# SSE320 register map
Vendor: ARM Ltd.; Series: ARMv8.1-M Mainline; File version: 1.0
CPU: CM85 r0p0, little endian, MPU, FPU, 3 interrupt priority bits, 8 SAU regions
Registers are 32-bit, read-write, reset 0x0 unless marked. A register's access mark holds for its fields unless they carry their own. Offsets are from the block's base; [hi:lo] are bit positions; {n}, {i} and the like mark numbered series.

## UART0
Base 0x48203000
Same registers: UART1 0x48204000, UART2 0x48205000, UART3 0x48206000, UART4 0x48207000, UART5 0x48208000, UART0_Secure 0x58203000, UART1_Secure 0x58204000, UART2_Secure 0x58205000, UART3_Secure 0x58206000, UART4_Secure 0x58207000, UART5_Secure 0x58208000
0x00 DATA 8-bit — Receive and Transmit Data Value
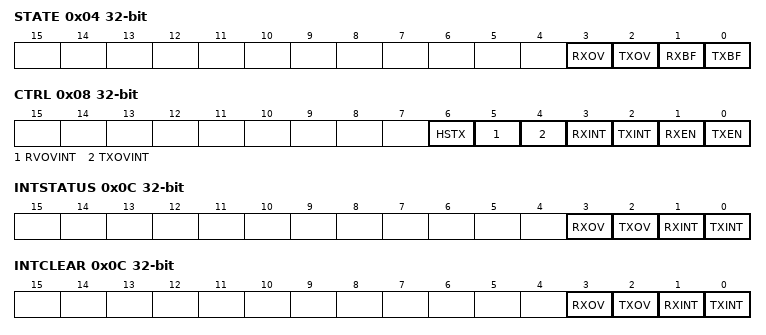
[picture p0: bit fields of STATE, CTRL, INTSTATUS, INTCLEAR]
0x04 STATE — UART Status Register
  [3] RXOV write-1-clears — RX Buffer Overun (write 1 to clear)
  [2] TXOV write-1-clears — TX Buffer Overun (write 1 to clear)
  [1] RXBF ro — RX Buffer Full
  [0] TXBF ro — TX Buffer Full
0x08 CTRL — UART Control Register
  [all] fields
    0=Disabled; 1=Enabled
  [6] HSTX — High Speed Test Mode for TX only
  [5] RVOVINT — RX Overrun Interrupt Enable
  [4] TXOVINT — TX Overrun Interrupt Enable
  [3] RXINT — RX Interrupt Enable
  [2] TXINT — TX Interrupt Enable
  [1] RXEN — RX Enable
  [0] TXEN — TX Enable
0x0C INTSTATUS ro — UART Interrupt Status Register
  [3] RXOV — RX Overrun Interrupt
  [2] TXOV — TX Overrun Interrupt
  [1] RXINT — RX Interrupt
  [0] TXINT — TX Interrupt
0x0C INTCLEAR wo (alternate view of INTSTATUS) — UART Interrupt CLEAR Register
  [3] RXOV write-1-clears — RX Overrun Interrupt
  [2] TXOV write-1-clears — TX Overrun Interrupt
  [1] RXINT write-1-clears — RX Interrupt
  [0] TXINT write-1-clears — TX Interrupt
0x10 BAUDDIV — Baudrate Divider

## I2C0 — I2C Touch
Base 0x48100000
Same registers: I2C1 0x48105000, I2C2 0x48106000, I2C3 0x48108000, I2C3 0x48109000, I2C0_Secure 0x58100000, I2C2 0x58105000, I2C3 0x58106000, I2C3 0x58108000, I2C3 0x58109000
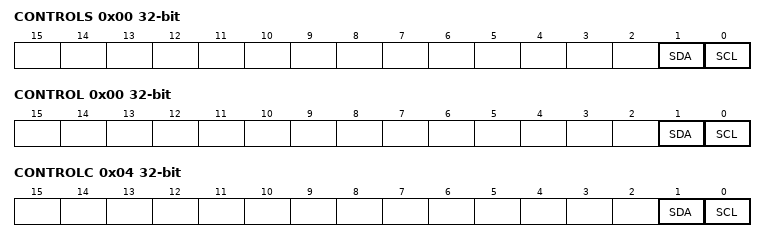
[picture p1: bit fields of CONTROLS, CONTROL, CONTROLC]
0x00 CONTROLS wo — Control Set
  [1] SDA — Serial data line
  [0] SCL — Serial clock line
0x00 CONTROL ro (alternate view of CONTROLS) — Control Status
  [1] SDA — Serial data line
  [0] SCL — Serial clock line
0x04 CONTROLC — Control Clear
  [1] SDA — Serial data line
  [0] SCL — Serial clock line

## WATCHDOG — Non-secure Watchdog Timer
Base 0x48040000
Same registers: WATCHDOG_Secure 0x58040000
0x00 WCS — Watchdog control and Status.
0x08 WOR — Watchdog Offset Register.
0x10 WCV_LOW — Watchdog Compare Value Lower Word.
0x14 WCV_HIGH — Watchdog Compare Value Higher Word.
0xFCC CNT_W_IIDR ro reset 0x143B — Control Frame Watchdog Interface Identification Register.
0x1000 WRR wo — Watchdog Refresh Register.
0x1FCC REF_W_IIDR ro reset 0x143B — Refresh Frame Watchdog Interface Identification Register.

## FPGAIO — FPGA System Control I/O
Base 0x48202000
Same registers: FPGAIO_Secure 0x58202000
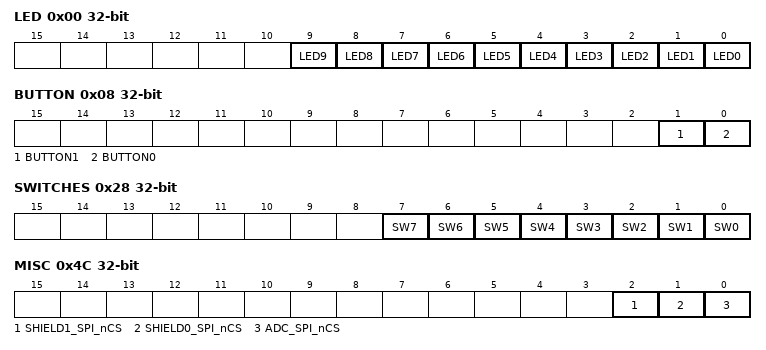
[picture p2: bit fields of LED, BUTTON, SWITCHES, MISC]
0x00 LED — LED Connections
  [all] fields
    0=Off (LED is off); 1=On (LED is on)
  [n] LED{n} (n=0..9)
0x08 BUTTON — Button Connections
  [1] BUTTON1
    0=Off (BUTTON is off); 1=On (BUTTON is on)
  [0] BUTTON0
    0=Off (BUTTON is off); 1=On (BUTTON is on)
0x10 CLK1HZ ro — 1Hz Up Counter
0x14 CLK100HZ ro — 100Hz Up Counter
0x18 COUNTER — Cycle up counter
0x1C PRESCALER — Reload value for prescaler counter
0x20 PSCNTR — Prescale Counter
0x28 SWITCHES ro — User Switches
  [all] fields
    0=Off (Switch is Off); 1=On (Switch is On)
  [n] SW{n} (n=0..7)
0x4C MISC — Misc. Control
  [2] SHIELD1_SPI_nCS, [1] SHIELD0_SPI_nCS, [0] ADC_SPI_nCS

## SCC — Serial Communication Controller
Base 0x48200000
Same registers: SCC_Secure 0x58200000
0x00 CFG_REG0
  [0] REMAP — 1 = REMAP Block RAM to ZBT
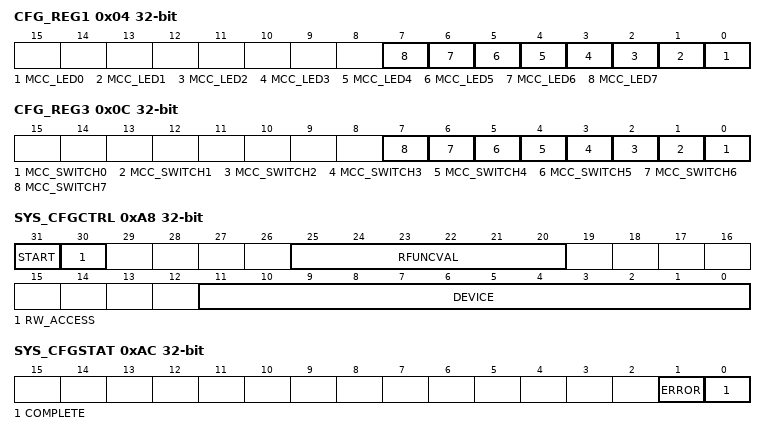
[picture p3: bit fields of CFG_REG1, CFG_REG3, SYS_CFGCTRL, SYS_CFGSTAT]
0x04 CFG_REG1
  [all] fields
    0=Off (LED is off); 1=On (LED is on)
  [n] MCC_LED{n} (n=0..7) — MCC LEDs: 0 = OFF 1 = ON
0x08 CFG_REG2 ro
0x0C CFG_REG3 ro
  [all] fields
    0=Off (Switch is off); 1=On (Switch is on)
  [n] MCC_SWITCH{n} (n=0..7) — MCC SWITCHES: 0 = OFF 1 = ON
0x10 CFG_REG4 ro
  [3:0] BRDREV — Board Revision
0x14 CFG_REG5
  [5] DEBUG — Debug: 0 = Serial Wire Debug 1 = JTAG
0x18 CFG_REG6 ro
0x1C CFG_REG7 ro
0xA0 SYS_CFGDATA_RTN
0xA4 SYS_CFGDATA_OUT
0xA8 SYS_CFGCTRL
  [31] START — Start: generates interrupt on write to this bit
  [30] RW_ACCESS — Read/Write Access
  [25:20] RFUNCVAL — Function Value
  [11:0] DEVICE — Device (value of 0/1/2 for supported clocks
0xAC SYS_CFGSTAT
  [1] ERROR — Error Flag
  [0] COMPLETE — Complete Flag
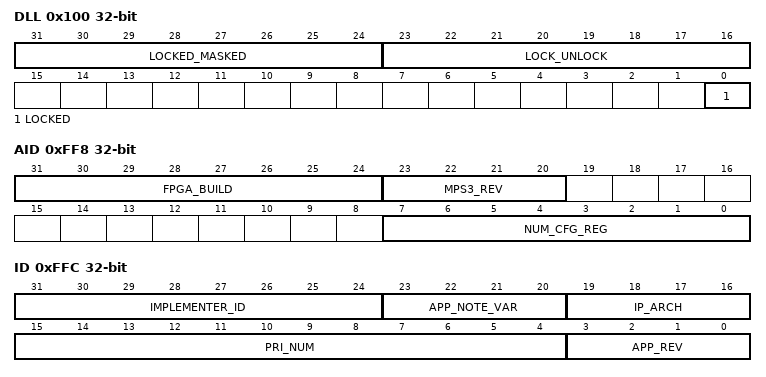
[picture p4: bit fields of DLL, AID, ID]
0x100 DLL — DLL Lock Register
  [31:24] LOCKED_MASKED — Error Flag
  [23:16] LOCK_UNLOCK — Complete Flag
  [0] LOCKED — Complete Flag
0xFF8 AID ro
  [31:24] FPGA_BUILD — FPGA Build Number
  [23:20] MPS3_REV — V2M-MPS3 target Board Revision (A=0,B=1,C=2)
  [7:0] NUM_CFG_REG — Number of SCC configuration register
0xFFC ID ro
  [31:24] IMPLEMENTER_ID — Implementer ID: 0x41 = ARM
  [23:20] APP_NOTE_VAR — Application note IP variant number
  [19:16] IP_ARCH — IP Architecture: 0x4 = AHB
  [15:4] PRI_NUM — Primary Part Number: 521 = AN521
  [3:0] APP_REV — Application note IP revision number
